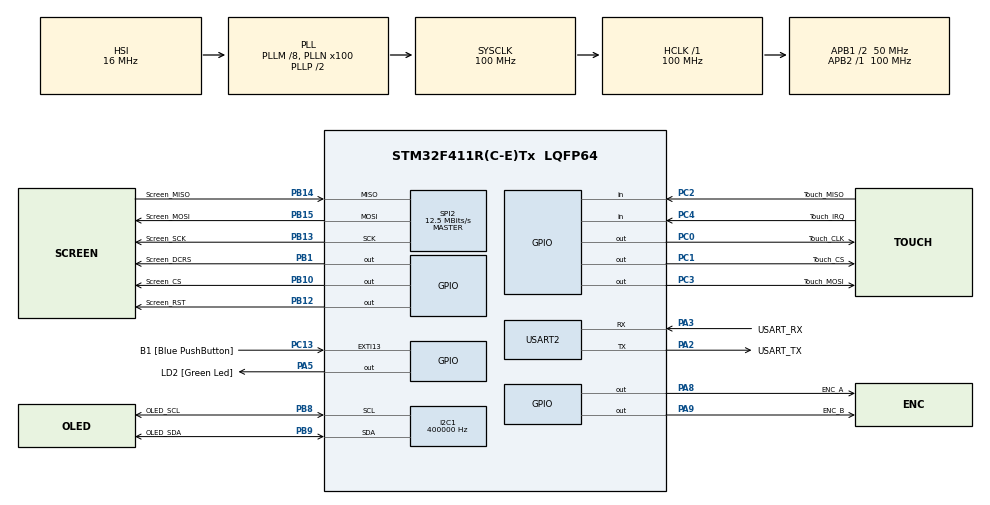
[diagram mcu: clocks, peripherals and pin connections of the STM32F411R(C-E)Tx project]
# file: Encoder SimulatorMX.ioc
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Dma.I2C1_TX.0.Direction=DMA_MEMORY_TO_PERIPH
Dma.I2C1_TX.0.FIFOMode=DMA_FIFOMODE_DISABLE
Dma.I2C1_TX.0.Instance=DMA1_Stream6
Dma.I2C1_TX.0.MemDataAlignment=DMA_MDATAALIGN_BYTE
Dma.I2C1_TX.0.MemInc=DMA_MINC_ENABLE
Dma.I2C1_TX.0.Mode=DMA_NORMAL
Dma.I2C1_TX.0.PeriphDataAlignment=DMA_PDATAALIGN_BYTE
Dma.I2C1_TX.0.PeriphInc=DMA_PINC_DISABLE
Dma.I2C1_TX.0.Priority=DMA_PRIORITY_LOW
Dma.Request0=I2C1_TX
I2C1.ClockSpeed=400000
I2C1.I2C_Speed_Mode=I2C_Fast
Mcu.Family=STM32F4
Mcu.Name=STM32F411R(C-E)Tx
Mcu.Package=LQFP64
NVIC.DMA1_Stream6_IRQn=true\:2\:0\:false\:false\:true\:false\:true\:true
NVIC.I2C1_ER_IRQn=true\:2\:0\:false\:false\:true\:true\:true\:true
NVIC.I2C1_EV_IRQn=true\:2\:0\:false\:false\:true\:true\:true\:true
NVIC.PriorityGroup=NVIC_PRIORITYGROUP_4
NVIC.TIM2_IRQn=true\:0\:0\:false\:false\:true\:true\:true\:true
NVIC.USART2_IRQn=true\:1\:0\:false\:false\:true\:true\:true\:true
PA13.GPIO_Label=TMS
PA13.Mode=Serial_Wire
PA13.Signal=SYS_JTMS-SWDIO
PA14.GPIO_Label=TCK
PA14.Mode=Serial_Wire
PA14.Signal=SYS_JTCK-SWCLK
PA2.GPIO_Label=USART_TX
PA2.Mode=Asynchronous
PA2.Signal=USART2_TX
PA3.GPIO_Label=USART_RX
PA3.Mode=Asynchronous
PA3.Signal=USART2_RX
PA5.GPIO_Label=LD2 [Green Led]
PA5.Signal=GPIO_Output
PA8.GPIO_Label=ENC_A
PA8.PinState=GPIO_PIN_RESET
PA8.Signal=GPIO_Output
PA9.GPIO_Label=ENC_B
PA9.PinState=GPIO_PIN_RESET
PA9.Signal=GPIO_Output
PB1.GPIO_Label=Screen_DCRS
PB1.GPIO_Speed=GPIO_SPEED_FREQ_VERY_HIGH
PB1.Signal=GPIO_Output
PB10.GPIO_Label=Screen_CS
PB10.GPIO_Speed=GPIO_SPEED_FREQ_VERY_HIGH
PB10.PinState=GPIO_PIN_SET
PB10.Signal=GPIO_Output
PB12.GPIO_Label=Screen_RST
PB12.GPIO_Speed=GPIO_SPEED_FREQ_VERY_HIGH
PB12.Signal=GPIO_Output
PB13.GPIO_Label=Screen_SCK
PB13.Mode=Full_Duplex_Master
PB13.Signal=SPI2_SCK
PB14.GPIO_Label=Screen_MISO
PB14.Mode=Full_Duplex_Master
PB14.Signal=SPI2_MISO
PB15.GPIO_Label=Screen_MOSI
PB15.Mode=Full_Duplex_Master
PB15.Signal=SPI2_MOSI
PB3.GPIO_Label=SWO
PB3.Signal=SYS_JTDO-SWO
PB8.GPIO_Label=OLED_SCL
PB8.GPIO_PuPd=GPIO_PULLUP
PB8.Mode=I2C
PB8.Signal=I2C1_SCL
PB9.GPIO_Label=OLED_SDA
PB9.GPIO_PuPd=GPIO_PULLUP
PB9.Mode=I2C
PB9.Signal=I2C1_SDA
PC0.GPIO_Label=Touch_CLK
PC0.GPIO_Speed=GPIO_SPEED_FREQ_HIGH
PC0.Signal=GPIO_Output
PC1.GPIO_Label=Touch_CS
PC1.GPIO_Speed=GPIO_SPEED_FREQ_HIGH
PC1.PinState=GPIO_PIN_SET
PC1.Signal=GPIO_Output
PC2.GPIO_Label=Touch_MISO
PC2.Signal=GPIO_Input
PC3.GPIO_Label=Touch_MOSI
PC3.GPIO_Speed=GPIO_SPEED_FREQ_HIGH
PC3.Signal=GPIO_Output
PC4.GPIO_Label=Touch_IRQ
PC4.GPIO_PuPd=GPIO_PULLUP
PC4.Signal=GPIO_Input
PC13-ANTI_TAMP.GPIO_Label=B1 [Blue PushButton]
PC13-ANTI_TAMP.GPIO_ModeDefaultEXTI=GPIO_MODE_IT_FALLING
PC13-ANTI_TAMP.Signal=GPXTI13
PC14-OSC32_IN.Mode=LSE-External-Oscillator
PC14-OSC32_IN.Signal=RCC_OSC32_IN
PC15-OSC32_OUT.Mode=LSE-External-Oscillator
PC15-OSC32_OUT.Signal=RCC_OSC32_OUT
PH0\ -\ OSC_IN.Mode=HSE-External-Clock-Source
PH0\ -\ OSC_IN.Signal=RCC_OSC_IN
PH1\ -\ OSC_OUT.Mode=HSE-External-Clock-Source
PH1\ -\ OSC_OUT.Signal=RCC_OSC_OUT
ProjectManager.HeapSize=0x200
ProjectManager.StackSize=0x400
ProjectManager.TargetToolchain=STM32CubeIDE
RCC.48MHZClocksFreq_Value=50000000
RCC.AHBFreq_Value=100000000
RCC.APB1CLKDivider=RCC_HCLK_DIV2
RCC.APB1Freq_Value=50000000
RCC.APB1TimFreq_Value=100000000
RCC.APB2Freq_Value=100000000
RCC.APB2TimFreq_Value=100000000
RCC.CortexFreq_Value=100000000
RCC.FLatency-AdvancedSettings=FLASH_LATENCY_3
RCC.HCLKFreq_Value=100000000
RCC.HSE_VALUE=8000000
RCC.HSI_VALUE=16000000
RCC.PLLM=8
RCC.PLLN=100
RCC.SYSCLKFreq_VALUE=100000000
RCC.SYSCLKSource=RCC_SYSCLKSOURCE_PLLCLK
RCC.VCOOutputFreq_Value=200000000
SPI2.BaudRatePrescaler=SPI_BAUDRATEPRESCALER_4
SPI2.CalculateBaudRate=12.5 MBits/s
SPI2.Direction=SPI_DIRECTION_2LINES
SPI2.Mode=SPI_MODE_MASTER
SPI2.VirtualType=VM_MASTER
TIM2.AutoReloadPreload=TIM_AUTORELOAD_PRELOAD_ENABLE
USART2.VirtualMode=VM_ASYNC
VP_TIM2_VS_ClockSourceINT.Mode=Internal
board=NUCLEO-F411RE

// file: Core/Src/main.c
/* USER CODE BEGIN Header */
/**
  ******************************************************************************
  * @file           : main.c
  * @brief          : Main program body
  ******************************************************************************
  * @attention
  *
  * Copyright (c) 2026 STMicroelectronics.
  * All rights reserved.
  *
  * This software is licensed under terms that can be found in the LICENSE file
  * in the root directory of this software component.
  * If no LICENSE file comes with this software, it is provided AS-IS.
  *
  ******************************************************************************
  */
/* USER CODE END Header */
#include "main.h"
#include "dma.h"
#include "i2c.h"
#include "tim.h"
#include "spi.h"
#include "usart.h"
#include "gpio.h"

/* USER CODE BEGIN Includes */
#include "encoder_sim.h"
#include "cmd_parser.h"
#include "ui.h"

/* USER CODE END Includes */

void SystemClock_Config(void);

int main(void)
{

  /* MCU Configuration--------------------------------------------------------*/

  /* Reset of all peripherals, Initializes the Flash interface and the Systick. */
  HAL_Init();

  /* Configure the system clock */
  SystemClock_Config();

  /* Initialize all configured peripherals */
  MX_GPIO_Init();
  MX_DMA_Init();
  MX_TIM2_Init();
  MX_USART2_UART_Init();
  MX_SPI2_Init();
  MX_I2C1_Init();
  /* USER CODE BEGIN 2 */
  ENC_Init();
  UI_Init();            /* ecran TFT ILI9341 (~0,3 s) */
  CMD_Init();

  /* USER CODE END 2 */

  /* Infinite loop */
  while (1)
  {

    /* USER CODE BEGIN 3 */
    CMD_Process();
    UI_Task();           /* rafraichissement ecran toutes les 100 ms */
  }
  /* USER CODE END 3 */
}

void SystemClock_Config(void)
{
  RCC_OscInitTypeDef RCC_OscInitStruct = {0};
  RCC_ClkInitTypeDef RCC_ClkInitStruct = {0};

  /** Configure the main internal regulator output voltage
  */
  __HAL_RCC_PWR_CLK_ENABLE();
  __HAL_PWR_VOLTAGESCALING_CONFIG(PWR_REGULATOR_VOLTAGE_SCALE1);

  /** Initializes the RCC Oscillators according to the specified parameters
  * in the RCC_OscInitTypeDef structure.
  */
  RCC_OscInitStruct.OscillatorType = RCC_OSCILLATORTYPE_HSI;
  RCC_OscInitStruct.HSIState = RCC_HSI_ON;
  RCC_OscInitStruct.HSICalibrationValue = RCC_HSICALIBRATION_DEFAULT;
  RCC_OscInitStruct.PLL.PLLState = RCC_PLL_ON;
  RCC_OscInitStruct.PLL.PLLSource = RCC_PLLSOURCE_HSI;
  RCC_OscInitStruct.PLL.PLLM = 8;
  RCC_OscInitStruct.PLL.PLLN = 100;
  RCC_OscInitStruct.PLL.PLLP = RCC_PLLP_DIV2;
  RCC_OscInitStruct.PLL.PLLQ = 4;
  if (HAL_RCC_OscConfig(&RCC_OscInitStruct) != HAL_OK)
  {
    Error_Handler();
  }

  /** Initializes the CPU, AHB and APB buses clocks
  */
  RCC_ClkInitStruct.ClockType = RCC_CLOCKTYPE_HCLK|RCC_CLOCKTYPE_SYSCLK
                              |RCC_CLOCKTYPE_PCLK1|RCC_CLOCKTYPE_PCLK2;
  RCC_ClkInitStruct.SYSCLKSource = RCC_SYSCLKSOURCE_PLLCLK;
  RCC_ClkInitStruct.AHBCLKDivider = RCC_SYSCLK_DIV1;
  RCC_ClkInitStruct.APB1CLKDivider = RCC_HCLK_DIV2;
  RCC_ClkInitStruct.APB2CLKDivider = RCC_HCLK_DIV1;

  if (HAL_RCC_ClockConfig(&RCC_ClkInitStruct, FLASH_LATENCY_3) != HAL_OK)
  {
    Error_Handler();
  }
}

void Error_Handler(void)
{
  __disable_irq();
  while (1)
  {
  }
}
